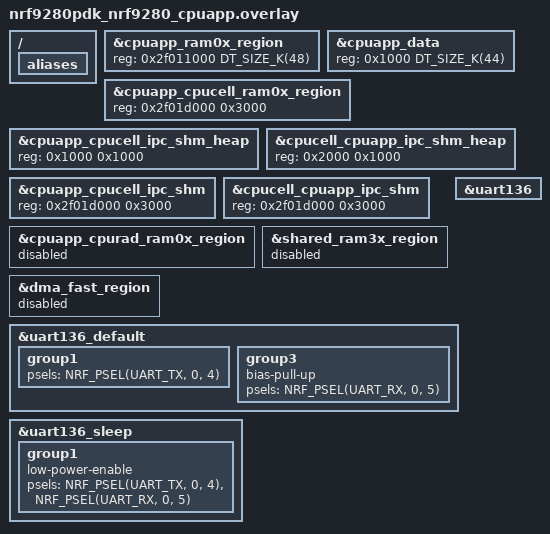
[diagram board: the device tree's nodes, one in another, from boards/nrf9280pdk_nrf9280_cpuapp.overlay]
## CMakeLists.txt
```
#
# Copyright (c) 2024 Nordic Semiconductor
#
# SPDX-License-Identifier: LicenseRef-Nordic-5-Clause
#

cmake_minimum_required(VERSION 3.20.0)

find_package(Zephyr REQUIRED HINTS $ENV{ZEPHYR_BASE})
project(nrf92_cloud_gnss)

zephyr_library_sources(src/main.c)
```

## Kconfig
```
#
# Copyright (c) 2024 Nordic Semiconductor ASA
#
# SPDX-License-Identifier: LicenseRef-Nordic-5-Clause
#

menu "nRF92 Cloud GNSS"
endmenu

menu "Zephyr Kernel"
source "Kconfig.zephyr"
endmenu

module = NRF92_CLOUD_GNSS
module-str = nRF92 Cloud GNSS
source "${ZEPHYR_BASE}/subsys/logging/Kconfig.template.log_config"
```

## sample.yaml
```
sample:
  name: nRF92 Cloud GNSS
tests:
  sample.cellular.nrf92_cloud_gnss:
    sysbuild: true
    build_only: true
    integration_platforms:
      - nrf9280pdk/nrf9280/cpuapp
    platform_allow:
      - nrf9280pdk/nrf9280/cpuapp
    tags: ci_build sysbuild ci_samples_cellular
```

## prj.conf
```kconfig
#
# Copyright (c) 2024 Nordic Semiconductor ASA
#
# SPDX-License-Identifier: LicenseRef-Nordic-5-Clause
#

# General
CONFIG_FPU=y
CONFIG_DCACHE=n
CONFIG_NRFS=n
CONFIG_LOG=y

# Memory and stack configuration
CONFIG_HEAP_MEM_POOL_SIZE=2048
#CONFIG_MAIN_STACK_SIZE=4096
#CONFIG_SYSTEM_WORKQUEUE_STACK_SIZE=1536

# Networking
CONFIG_NETWORKING=y
CONFIG_POSIX_API=y
# Disable native network stack to save some memory
CONFIG_NET_NATIVE=n
#CONFIG_NET_SOCKETS_TLS_SET_MAX_FRAGMENT_LENGTH=y
#CONFIG_NET_SOCKETS_OFFLOAD_PRIORITY=40

# nRF Modem library
CONFIG_NRF_MODEM_LIB=y

# LTE Link Control
CONFIG_LTE_LINK_CONTROL=y
CONFIG_LTE_EDRX_REQ=y
CONFIG_LTE_EDRX_REQ_VALUE_LTE_M="0101"
CONFIG_LTE_EDRX_REQ_VALUE_NBIOT="0101"

# Location library
CONFIG_LOCATION=y
CONFIG_LOCATION_METHOD_CELLULAR=n

# Modem info library
CONFIG_MODEM_INFO=y

CONFIG_DATE_TIME=y

# nRF Cloud
CONFIG_NRF_CLOUD_COAP=y
CONFIG_NRF_CLOUD_AGNSS=y
CONFIG_NRF_CLOUD_PGPS=n
CONFIG_NRF_CLOUD_ALERT=n
CONFIG_NRF_CLOUD_LOG_DIRECT=n
CONFIG_NRF_CLOUD_SEND_DEVICE_STATUS=n
CONFIG_NRF_CLOUD_SEND_DEVICE_STATUS_NETWORK=n
CONFIG_NRF_CLOUD_SEND_DEVICE_STATUS_SIM=n
CONFIG_NRF_CLOUD_SEND_DEVICE_STATUS_CONN_INF=n
CONFIG_NRF_CLOUD_SEND_SERVICE_INFO_FOTA=n
CONFIG_NRF_CLOUD_FOTA=n
CONFIG_NRF_CLOUD_LOCATION=n

# Modem
CONFIG_MODEM_KEY_MGMT=y
CONFIG_MODEM_JWT=y

# CoAP Client
CONFIG_COAP_CLIENT_BLOCK_SIZE=1024
CONFIG_COAP_CLIENT_STACK_SIZE=6144
CONFIG_COAP_CLIENT_THREAD_PRIORITY=0
CONFIG_COAP_EXTENDED_OPTIONS_LEN_VALUE=40
```

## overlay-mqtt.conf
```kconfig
#
# Copyright (c) 2024 Nordic Semiconductor
#
# SPDX-License-Identifier: LicenseRef-Nordic-5-Clause
#

CONFIG_HEAP_MEM_POOL_SIZE=3072

CONFIG_NRF_CLOUD_COAP=n
CONFIG_NRF_CLOUD_MQTT=y
CONFIG_NRF_CLOUD_CLIENT_ID_SRC_COMPILE_TIME=y
CONFIG_NRF_CLOUD_CLIENT_ID="nrf-359746166786272"

CONFIG_MQTT_CLEAN_SESSION=y

CONFIG_MODEM_KEY_MGMT=n
CONFIG_MODEM_JWT=n
```

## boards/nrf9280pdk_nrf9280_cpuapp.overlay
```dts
/ {
	/* Delete these aliases because the button nodes are deleted. */
	aliases {
		/delete-property/ sw0;
		/delete-property/ sw1;
		/delete-property/ sw3;
	};
};

/* Remove buttons because they conflict with modem pin allocations. */
/delete-node/ &button0;
/delete-node/ &button1;
/delete-node/ &button3;

&cpuapp_ram0x_region {
	reg = < 0x2f011000 DT_SIZE_K(48) >;
	ranges = < 0x0 0x2f011000 0xC000 >;
};
&cpuapp_data {
	reg = < 0x1000 DT_SIZE_K(44) >;
};

&cpuapp_cpucell_ram0x_region {
	reg = < 0x2f01d000 0x3000 >;
	ranges = < 0x0 0x2f01d000 0x3000 >;
};

&cpuapp_cpucell_ipc_shm_heap {
	reg = < 0x1000 0x1000 >;
};

&cpucell_cpuapp_ipc_shm_heap {
	reg = < 0x2000 0x1000 >;
};

&cpuapp_cpucell_ipc_shm {
	reg = < 0x2f01d000 0x3000 >;
};

&cpucell_cpuapp_ipc_shm {
	reg = < 0x2f01d000 0x3000 >;
};

&cpuapp_cpurad_ram0x_region {
	status = "disabled";
};

// Should be fixed in zephyr upstream
/* Access given by default. Blocks boot if access is asked for through UICR. */
&shared_ram3x_region {
	status = "disabled";
};

&dma_fast_region {
        status = "disabled";
};

/* Disable HW flow control for the application UART. CTS is connected to pin P0.0, but
 * pins 0..3 cannot be used for UARTE signals.
 */
&uart136 {
	/*current-speed = <1000000>;*/
	/delete-property/ hw-flow-control;
};

&uart136_default {
	group1 {
		psels = <NRF_PSEL(UART_TX, 0, 4)>;
	};
	group3 {
		bias-pull-up;
		psels = <NRF_PSEL(UART_RX, 0, 5)>;
	};
};
&uart136_sleep {
	group1 {
		low-power-enable;
		psels = <NRF_PSEL(UART_TX, 0, 4)>,
			<NRF_PSEL(UART_RX, 0, 5)>;
	};
};
```

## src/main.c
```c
/*
 * Copyright (c) 2024 Nordic Semiconductor ASA
 *
 * SPDX-License-Identifier: LicenseRef-Nordic-5-Clause
 */

#include <zephyr/kernel.h>
#include <zephyr/logging/log.h>
#include <modem/nrf_modem_lib.h>
#include <modem/lte_lc.h>
#include <modem/location.h>
#include <date_time.h>
#if defined(CONFIG_NRF_CLOUD_COAP)
#include <net/nrf_cloud_coap.h>
#else
#include <net/nrf_cloud.h>
#include <net/nrf_cloud_codec.h>
#endif

LOG_MODULE_REGISTER(nrf92_cloud_gnss, CONFIG_NRF92_CLOUD_GNSS_LOG_LEVEL);

struct nrf_cloud_gnss_data gnss_data = {
	.type = NRF_CLOUD_GNSS_TYPE_PVT
};

static void location_get_work_fn(struct k_work *work);
K_WORK_DELAYABLE_DEFINE(location_get_work, location_get_work_fn);

static void location_get_work_fn(struct k_work *work)
{
	int err;

	LOG_INF("Requesting location...");

	err = location_request(NULL);
	if (err) {
		LOG_ERR("Failed to request location, error: %d", err);
	}

	k_work_schedule(&location_get_work, K_MINUTES(5));
}

#if defined(CONFIG_NRF_CLOUD_COAP)
static int cloud_location_coap_send(void)
{
	int err = nrf_cloud_coap_location_send(&gnss_data, true);
	if (err) {
		LOG_ERR("Failed to send CoAP message, error: %d", err);
	}

	return err;
}
#endif /* CONFIG_NRF_CLOUD_COAP */

#if defined(CONFIG_NRF_CLOUD_MQTT)
static int cloud_payload_json_encode(char **json_str_out)
{
	int err;

	cJSON *gnss_data_obj = cJSON_CreateObject();
	if (gnss_data_obj == NULL) {
		err = -ENOMEM;
		goto cleanup;
	}

	err = nrf_cloud_gnss_msg_json_encode(&gnss_data, gnss_data_obj);
	if (err) {
		LOG_ERR("Failed to encode GNSS device message, error: %d", err);
		goto cleanup;
	}

	*json_str_out = cJSON_PrintUnformatted(gnss_data_obj);
	if (*json_str_out == NULL) {
		err = -ENOMEM;
	}

cleanup:
	if (gnss_data_obj) {
		cJSON_Delete(gnss_data_obj);
	}

	return err;
}

static int cloud_location_mqtt_send(void)
{
	int err;
	char *json_payload = NULL;

	err = cloud_payload_json_encode(&json_payload);
	if (err) {
		LOG_ERR("Failed to encode cloud payload, error: %d", err);
		return err;
	}

	struct nrf_cloud_tx_data mqtt_msg = {
		.data.ptr = json_payload,
                .data.len = strlen(json_payload),
                .qos = MQTT_QOS_1_AT_LEAST_ONCE,
                .topic_type = NRF_CLOUD_TOPIC_MESSAGE,
        };

        err = nrf_cloud_send(&mqtt_msg);
        if (err) {
                LOG_ERR("Failed to send MQTT message, error: %d", err);
        }

	if (json_payload) {
		cJSON_free(json_payload);
	}

	return err;
}
#endif /* CONFIG_NRF_CLOUD_MQTT */

static void location_send_work_fn(struct k_work *work)
{
	int err;

#if defined(CONFIG_NRF_CLOUD_COAP)
	err = cloud_location_coap_send();
#else
	err = cloud_location_mqtt_send();
#endif
	if (err) {
		LOG_ERR("Failed to send location to cloud");
	} else {
		LOG_INF("Location sent to cloud");
	}
}

K_WORK_DEFINE(location_send_work, location_send_work_fn);

static void lte_lc_event_handler(const struct lte_lc_evt *const evt)
{
	switch (evt->type) {
	case LTE_LC_EVT_NW_REG_STATUS:
		switch (evt->nw_reg_status) {
		case LTE_LC_NW_REG_NOT_REGISTERED:
			LOG_INF("Registration status: not registered");
			break;

		case LTE_LC_NW_REG_REGISTERED_HOME:
			LOG_INF("Registration status: registered, home");
			break;

		case LTE_LC_NW_REG_SEARCHING:
			LOG_INF("Registration status: searching");
			break;

		case LTE_LC_NW_REG_REGISTRATION_DENIED:
			LOG_INF("Registration status: registration denied");
			break;

		case LTE_LC_NW_REG_UNKNOWN:
			LOG_INF("Registration status: unknown");
			break;

		case LTE_LC_NW_REG_REGISTERED_ROAMING:
			LOG_INF("Registration status: registered, roaming");
			break;

		case LTE_LC_NW_REG_UICC_FAIL:
			LOG_INF("Registration status: UICC failure");
			break;
	
		}

	default:
		break;
	}
}

#if defined(CONFIG_NRF_CLOUD_MQTT)
static void nrf_cloud_event_handler(const struct nrf_cloud_evt *evt)
{
	switch (evt->type) {
	case NRF_CLOUD_EVT_TRANSPORT_CONNECTED:
		LOG_INF("nRF Cloud event: transport connected");
		break;

	case NRF_CLOUD_EVT_TRANSPORT_CONNECTING:
		LOG_INF("nRF Cloud event: transport connecting");
		break;

	case NRF_CLOUD_EVT_USER_ASSOCIATION_REQUEST:
		LOG_INF("nRF Cloud event: user association request");
		break;

	case NRF_CLOUD_EVT_USER_ASSOCIATED:
		LOG_INF("nRF Cloud event: user associated");
		break;

	case NRF_CLOUD_EVT_READY:
		LOG_INF("nRF Cloud event: ready");
		k_work_schedule(&location_get_work, K_NO_WAIT);
		break;

	case NRF_CLOUD_EVT_RX_DATA_GENERAL:
		LOG_INF("nRF Cloud event: non-specific data received");
		break;

	case NRF_CLOUD_EVT_RX_DATA_DISCON:
		LOG_INF("nRF Cloud event: device removed from cloud");
		break;

	case NRF_CLOUD_EVT_RX_DATA_LOCATION:
		LOG_INF("nRF Cloud event: location data received");
		break;

	case NRF_CLOUD_EVT_RX_DATA_SHADOW:
		LOG_INF("nRF Cloud event: shadow data received");
		break;

	case NRF_CLOUD_EVT_PINGRESP:
		LOG_INF("nRF Cloud event: ping response received");
		break;

	case NRF_CLOUD_EVT_SENSOR_DATA_ACK:
		LOG_INF("nRF Cloud event: sensor data acknowledged");
		break;

	case NRF_CLOUD_EVT_TRANSPORT_DISCONNECTED:
		LOG_INF("nRF Cloud event: transport disconnected");
		break;

	case NRF_CLOUD_EVT_FOTA_START:
		LOG_INF("nRF Cloud event: FOTA started");
		break;

	case NRF_CLOUD_EVT_FOTA_DONE:
		LOG_INF("nRF Cloud event: FOTA finished");
		break;

	case NRF_CLOUD_EVT_FOTA_ERROR:
		LOG_INF("nRF Cloud event: error during FOTA update");
		break;

	case NRF_CLOUD_EVT_TRANSPORT_CONNECT_ERROR:
		LOG_INF("nRF Cloud event: error while connecting transport");
		break;

	case NRF_CLOUD_EVT_FOTA_JOB_AVAILABLE:
		LOG_INF("nRF Cloud event: FOTA job available");
		break;

	case NRF_CLOUD_EVT_ERROR:
		LOG_INF("nRF Cloud event: error");
		break;
	}
}
#endif

static void location_event_handler(const struct location_event_data *event_data)
{
	switch (event_data->id) {
	case LOCATION_EVT_LOCATION:
		LOG_INF("Location event: location update");
		date_time_now(&gnss_data.ts_ms);
		gnss_data.pvt.lon = event_data->location.longitude;
		gnss_data.pvt.lat = event_data->location.latitude;
		gnss_data.pvt.accuracy = event_data->location.accuracy;
		k_work_submit(&location_send_work);
		break;
	
	case LOCATION_EVT_TIMEOUT:
		LOG_INF("Location event: timeout");
		break;
	
	case LOCATION_EVT_ERROR:
		LOG_INF("Location event: error");
		break;
	
	case LOCATION_EVT_RESULT_UNKNOWN:
		LOG_INF("Location event: result unknown");
		break;
	
	case LOCATION_EVT_GNSS_ASSISTANCE_REQUEST:
		LOG_INF("Location event: GNSS assistance request");
		break;
	
	case LOCATION_EVT_GNSS_PREDICTION_REQUEST:
		LOG_INF("Location event: GNSS prediction request");
		break;
	
	case LOCATION_EVT_CLOUD_LOCATION_EXT_REQUEST:
		LOG_INF("Location event: external cloud request");
		break;
	
	case LOCATION_EVT_STARTED:
		LOG_INF("Location event: location request started");
		break;
	
	case LOCATION_EVT_FALLBACK:
		LOG_INF("Location event: fallback");
		break;
	}
}

int main(void)
{
	int err;

	LOG_INF("nRF92 Cloud GNSS sample started");

	err = nrf_modem_lib_init();
	if (err) {
		LOG_ERR("Modem library initialization failed, error: %d", err);
		return err;
	}

	lte_lc_register_handler(lte_lc_event_handler);

#if defined(CONFIG_NRF_CLOUD_COAP)
	err = nrf_cloud_coap_init();
#else
	const struct nrf_cloud_init_param cloud_params = {
		.event_handler = nrf_cloud_event_handler,
		.client_id = NULL
	};

	err = nrf_cloud_init(&cloud_params);
#endif
	if (err) {
		LOG_ERR("Failed to initialize nRF Cloud library, error: %d", err);
		return err;
	}

	err = location_init(location_event_handler);
	if (err) {
		LOG_ERR("Failed to initialize Location library, error: %d", err);
		return err;
	}

	LOG_INF("Connecting to LTE...");

	err = lte_lc_connect();
	if (err) {
		LOG_ERR("Failed to connect to LTE, error: %d", err);
		return err;
	}

	LOG_INF("Connecting to nRF Cloud...");

#if defined(CONFIG_NRF_CLOUD_COAP)
	err = nrf_cloud_coap_connect(NULL);
#else
	err = nrf_cloud_connect();
#endif
	if (err) {
		LOG_ERR("Failed to connect to nRF Cloud, error: %d", err);
		return err;
	}

	return 0;
}
```
